AUTOSAR XML (schema 4-2-2)
package /STELLANTIS/EPT/ASWCs
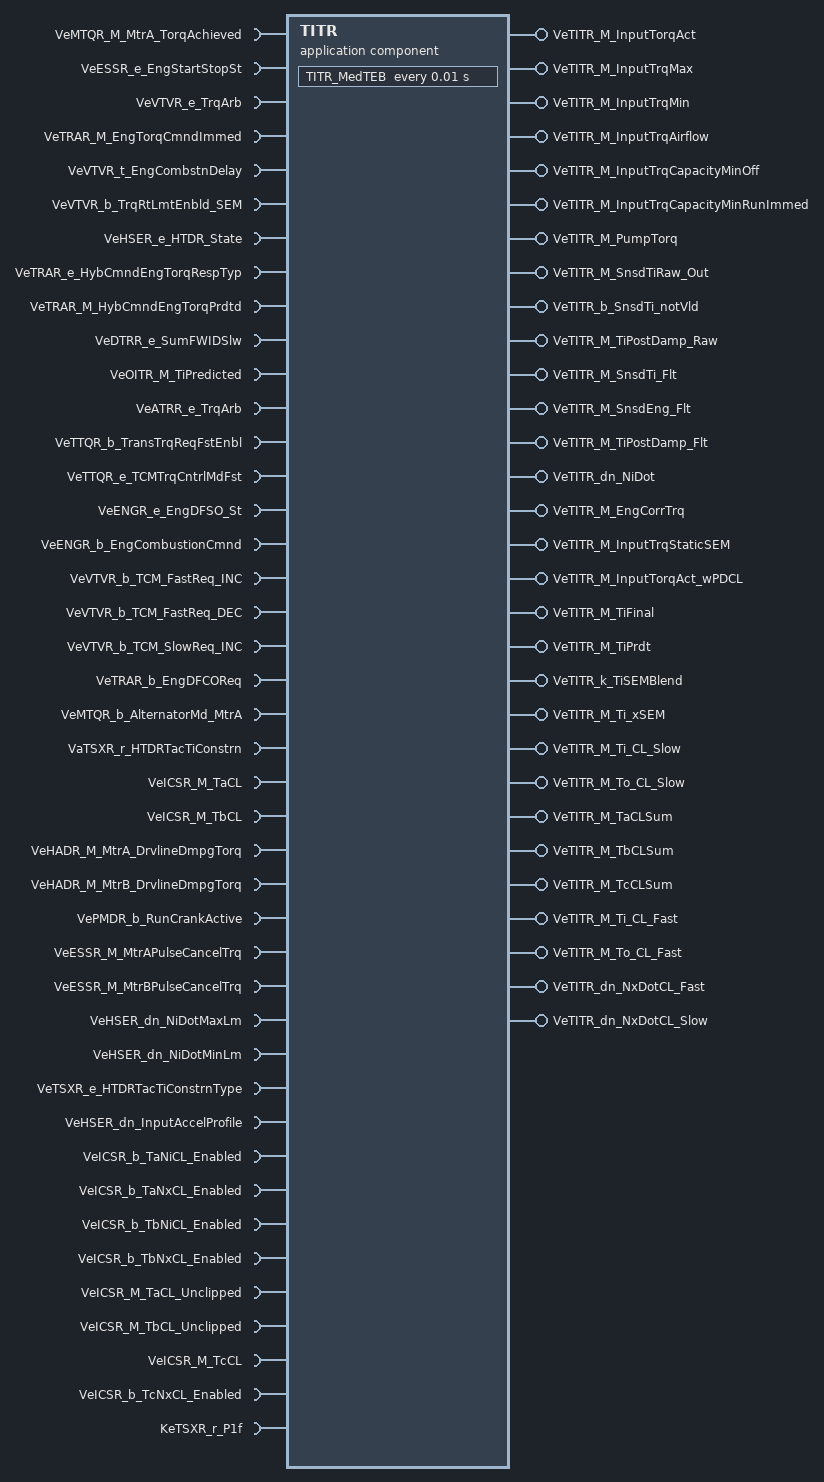
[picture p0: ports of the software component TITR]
  application sw component type TITR
    41 x require port:
      VeMTQR_M_MtrA_TorqAchieved: nonqueued-receiver-com-spec{data-element=Value, init-value=0}, required-interface=VeMTQR_M_MtrA_TorqAchieved
      VeESSR_e_EngStartStopSt: nonqueued-receiver-com-spec{data-element=Value, init-value=CeESSR_e_EngOff}, required-interface=VeESSR_e_EngStartStopSt
      VeVTVR_e_TrqArb: nonqueued-receiver-com-spec{data-element=Value, init-value=CeWTAR_e_ECM_TorqReqst}, required-interface=VeVTVR_e_TrqArb
      VeTRAR_M_EngTorqCmndImmed: nonqueued-receiver-com-spec{data-element=Value, init-value=0}, required-interface=VeTRAR_M_EngTorqCmndImmed
      VeVTVR_t_EngCombstnDelay: nonqueued-receiver-com-spec{data-element=Value, init-value=0}, required-interface=VeVTVR_t_EngCombstnDelay
      VeVTVR_b_TrqRtLmtEnbld_SEM: nonqueued-receiver-com-spec{data-element=Value, init-value=0}, required-interface=VeVTVR_b_TrqRtLmtEnbld_SEM
      VeHSER_e_HTDR_State: nonqueued-receiver-com-spec{data-element=Value, init-value=CeHSER_e_Neut_State}, required-interface=VeHSER_e_HTDR_State
      VeTRAR_e_HybCmndEngTorqRespTyp: nonqueued-receiver-com-spec{data-element=Value, init-value=CeTRAR_e_Inactive}, required-interface=VeTRAR_e_HybCmndEngTorqRespTyp
      VeTRAR_M_HybCmndEngTorqPrdtd: nonqueued-receiver-com-spec{data-element=Value, init-value=0}, required-interface=VeTRAR_M_HybCmndEngTorqPrdtd
      VeDTRR_e_SumFWIDSlw: nonqueued-receiver-com-spec{data-element=Value, init-value=CeDTRR_e_Potential}, required-interface=VeDTRR_e_SumFWIDSlw
      VeOITR_M_TiPredicted: nonqueued-receiver-com-spec{data-element=Value, init-value=0}, required-interface=VeOITR_M_TiPredicted
      VeATRR_e_TrqArb: nonqueued-receiver-com-spec{data-element=Value, init-value=CeWTAR_e_ECM_TorqReqst}, required-interface=VeATRR_e_TrqArb
      VeTTQR_b_TransTrqReqFstEnbl: nonqueued-receiver-com-spec{data-element=Value, init-value=0}, required-interface=VeTTQR_b_TransTrqReqFstEnbl
      VeTTQR_e_TCMTrqCntrlMdFst: nonqueued-receiver-com-spec{data-element=Value, init-value=CeTINR_e_None}, required-interface=VeTTQR_e_TCMTrqCntrlMdFst
      VeENGR_e_EngDFSO_St: nonqueued-receiver-com-spec{data-element=Value, init-value=CeENGR_e_DFSO_Disabled}, required-interface=VeENGR_e_EngDFSO_St
      VeENGR_b_EngCombustionCmnd: nonqueued-receiver-com-spec{data-element=Value, init-value=0}, required-interface=VeENGR_b_EngCombustionCmnd
      VeVTVR_b_TCM_FastReq_INC: nonqueued-receiver-com-spec{data-element=Value, init-value=0}, required-interface=VeVTVR_b_TCM_FastReq_INC
      VeVTVR_b_TCM_FastReq_DEC: nonqueued-receiver-com-spec{data-element=Value, init-value=0}, required-interface=VeVTVR_b_TCM_FastReq_DEC
      VeVTVR_b_TCM_SlowReq_INC: nonqueued-receiver-com-spec{data-element=Value, init-value=0}, required-interface=VeVTVR_b_TCM_SlowReq_INC
      VeTRAR_b_EngDFCOReq: nonqueued-receiver-com-spec{data-element=Value, init-value=0}, required-interface=VeTRAR_b_EngDFCOReq
      VeMTQR_b_AlternatorMd_MtrA: nonqueued-receiver-com-spec{data-element=Value, init-value=0}, required-interface=VeMTQR_b_AlternatorMd_MtrA
      VaTSXR_r_HTDRTacTiConstrn: nonqueued-receiver-com-spec{data-element=Value, init-value=114 x 0}, required-interface=VaTSXR_r_HTDRTacTiConstrn
      VeICSR_M_TaCL: nonqueued-receiver-com-spec{data-element=Value, init-value=0}, required-interface=VeICSR_M_TaCL
      VeICSR_M_TbCL: nonqueued-receiver-com-spec{data-element=Value, init-value=0}, required-interface=VeICSR_M_TbCL
      VeHADR_M_MtrA_DrvlineDmpgTorq: nonqueued-receiver-com-spec{data-element=Value, init-value=0}, required-interface=VeHADR_M_MtrA_DrvlineDmpgTorq
      VeHADR_M_MtrB_DrvlineDmpgTorq: nonqueued-receiver-com-spec{data-element=Value, init-value=0}, required-interface=VeHADR_M_MtrB_DrvlineDmpgTorq
      VePMDR_b_RunCrankActive: nonqueued-receiver-com-spec{data-element=Value, init-value=0}, required-interface=VePMDR_b_RunCrankActive
      VeESSR_M_MtrAPulseCancelTrq: nonqueued-receiver-com-spec{data-element=Value, init-value=0}, required-interface=VeESSR_M_MtrAPulseCancelTrq
      VeESSR_M_MtrBPulseCancelTrq: nonqueued-receiver-com-spec{data-element=Value, init-value=0}, required-interface=VeESSR_M_MtrBPulseCancelTrq
      VeHSER_dn_NiDotMaxLm: nonqueued-receiver-com-spec{data-element=Value, init-value=0}, required-interface=VeHSER_dn_NiDotMaxLm
      VeHSER_dn_NiDotMinLm: nonqueued-receiver-com-spec{data-element=Value, init-value=0}, required-interface=VeHSER_dn_NiDotMinLm
      VeTSXR_e_HTDRTacTiConstrnType: nonqueued-receiver-com-spec{data-element=Value, init-value=CeTSXR_e_Mode}, required-interface=VeTSXR_e_HTDRTacTiConstrnType
      VeHSER_dn_InputAccelProfile: nonqueued-receiver-com-spec{data-element=Value, init-value=0}, required-interface=VeHSER_dn_InputAccelProfile
      VeICSR_b_TaNiCL_Enabled: nonqueued-receiver-com-spec{data-element=Value, init-value=0}, required-interface=VeICSR_b_TaNiCL_Enabled
      VeICSR_b_TaNxCL_Enabled: nonqueued-receiver-com-spec{data-element=Value, init-value=0}, required-interface=VeICSR_b_TaNxCL_Enabled
      VeICSR_b_TbNiCL_Enabled: nonqueued-receiver-com-spec{data-element=Value, init-value=0}, required-interface=VeICSR_b_TbNiCL_Enabled
      VeICSR_b_TbNxCL_Enabled: nonqueued-receiver-com-spec{data-element=Value, init-value=0}, required-interface=VeICSR_b_TbNxCL_Enabled
      VeICSR_M_TaCL_Unclipped: nonqueued-receiver-com-spec{data-element=Value, init-value=0}, required-interface=VeICSR_M_TaCL_Unclipped
      VeICSR_M_TbCL_Unclipped: nonqueued-receiver-com-spec{data-element=Value, init-value=0}, required-interface=VeICSR_M_TbCL_Unclipped
      VeICSR_M_TcCL: nonqueued-receiver-com-spec{data-element=Value, init-value=0}, required-interface=VeICSR_M_TcCL
      VeICSR_b_TcNxCL_Enabled: nonqueued-receiver-com-spec{data-element=Value, init-value=0}, required-interface=VeICSR_b_TcNxCL_Enabled
    30 x provide port, all with nonqueued-sender-com-spec{data-element=Value, init-value=0}:
      VeTITR_M_InputTorqAct: variation-point={short-label=vpVeTITR_M_InputTorqAct, sw-syscond=1}, provided-interface=VeTITR_M_InputTorqAct
      VeTITR_M_InputTrqMax: variation-point={short-label=vpVeTITR_M_InputTrqMax, sw-syscond=1}, provided-interface=VeTITR_M_InputTrqMax
      VeTITR_M_InputTrqMin: variation-point={short-label=vpVeTITR_M_InputTrqMin, sw-syscond=1}, provided-interface=VeTITR_M_InputTrqMin
      VeTITR_M_InputTrqAirflow: variation-point={short-label=vpVeTITR_M_InputTrqAirflow, sw-syscond=1}, provided-interface=VeTITR_M_InputTrqAirflow
      VeTITR_M_InputTrqCapacityMinOff: variation-point={short-label=vpVeTITR_M_InputTrqCapacityMinOff, sw-syscond=1}, provided-interface=VeTITR_M_InputTrqCapacityMinOff
      VeTITR_M_InputTrqCapacityMinRunImmed: variation-point={short-label=vpVeTITR_M_InputTrqCapacityMinRunImmed, sw-syscond=1}, provided-interface=VeTITR_M_InputTrqCapacityMinRunImmed
      VeTITR_M_PumpTorq: variation-point={short-label=vpVeTITR_M_PumpTorq, sw-syscond=1}, provided-interface=VeTITR_M_PumpTorq
      VeTITR_M_SnsdTiRaw_Out: variation-point={short-label=vpVeTITR_M_SnsdTiRaw_Out, sw-syscond=1}, provided-interface=VeTITR_M_SnsdTiRaw_Out
      VeTITR_b_SnsdTi_notVld: variation-point={short-label=vpVeTITR_b_SnsdTi_notVld, sw-syscond=1}, provided-interface=VeTITR_b_SnsdTi_notVld
      VeTITR_M_TiPostDamp_Raw: variation-point={short-label=vpVeTITR_M_TiPostDamp_Raw, sw-syscond=1}, provided-interface=VeTITR_M_TiPostDamp_Raw
      VeTITR_M_SnsdTi_Flt: variation-point={short-label=vpVeTITR_M_SnsdTi_Flt, sw-syscond=1}, provided-interface=VeTITR_M_SnsdTi_Flt
      VeTITR_M_SnsdEng_Flt: variation-point={short-label=vpVeTITR_M_SnsdEng_Flt, sw-syscond=1}, provided-interface=VeTITR_M_SnsdEng_Flt
      VeTITR_M_TiPostDamp_Flt: variation-point={short-label=vpVeTITR_M_TiPostDamp_Flt, sw-syscond=1}, provided-interface=VeTITR_M_TiPostDamp_Flt
      VeTITR_dn_NiDot: variation-point={short-label=vpVeTITR_dn_NiDot, sw-syscond=1}, provided-interface=VeTITR_dn_NiDot
      VeTITR_M_EngCorrTrq: variation-point={short-label=vpVeTITR_M_EngCorrTrq, sw-syscond=1}, provided-interface=VeTITR_M_EngCorrTrq
      VeTITR_M_InputTrqStaticSEM: variation-point={short-label=vpVeTITR_M_InputTrqStaticSEM, sw-syscond=1}, provided-interface=VeTITR_M_InputTrqStaticSEM
      VeTITR_M_InputTorqAct_wPDCL: variation-point={short-label=vpVeTITR_M_InputTorqAct_wPDCL, sw-syscond=1}, provided-interface=VeTITR_M_InputTorqAct_wPDCL
      VeTITR_M_TiFinal: provided-interface=VeTITR_M_TiFinal
      VeTITR_M_TiPrdt: provided-interface=VeTITR_M_TiPrdt
      VeTITR_k_TiSEMBlend: provided-interface=VeTITR_k_TiSEMBlend
      VeTITR_M_Ti_xSEM: provided-interface=VeTITR_M_Ti_xSEM
      VeTITR_M_Ti_CL_Slow: provided-interface=VeTITR_M_Ti_CL_Slow
      VeTITR_M_To_CL_Slow: provided-interface=VeTITR_M_To_CL_Slow
      VeTITR_M_TaCLSum: provided-interface=VeTITR_M_TaCLSum
      VeTITR_M_TbCLSum: provided-interface=VeTITR_M_TbCLSum
      VeTITR_M_TcCLSum: provided-interface=VeTITR_M_TcCLSum
      VeTITR_M_Ti_CL_Fast: provided-interface=VeTITR_M_Ti_CL_Fast
      VeTITR_M_To_CL_Fast: provided-interface=VeTITR_M_To_CL_Fast
      VeTITR_dn_NxDotCL_Fast: provided-interface=VeTITR_dn_NxDotCL_Fast
      VeTITR_dn_NxDotCL_Slow: provided-interface=VeTITR_dn_NxDotCL_Slow
    require port KeTSXR_r_P1f: parameter-require-com-spec{init-value=KeTSXR_r_P1f_KeTSXR_r_P1f:2.55550003051758, parameter=KeTSXR_r_P1f}, required-interface=KeTSXR_r_P1f
    behavior IB_TITR: data-type-mapping=msADTtoIDTMapping, handle-termination-and-restart=NO-SUPPORT
      timing event Event_MedTEB: start-on-event=TITR_MedTEB, period=0.01
      init event Event_TITR_ac_Init: start-on-event=TITR_ac_Init
      init event Event_PUP: start-on-event=TITR_PUP
      init event Event_PwrOn: start-on-event=TITR_PwrOn
      4 x runnable:
        TITR_ac_Init
        TITR_PUP
          data-send-points:
            13 x access:
              OUT_VeTITR_M_InputTorqAct_Value: accessed-variable=VeTITR_M_InputTorqAct.Value, variation-point={short-label=vpOUT_VeTITR_M_InputTorqAct_Value, sw-syscond=1}
              OUT_VeTITR_M_InputTrqMax_Value: accessed-variable=VeTITR_M_InputTrqMax.Value, variation-point={short-label=vpOUT_VeTITR_M_InputTrqMax_Value, sw-syscond=1}
              OUT_VeTITR_M_InputTrqMin_Value: accessed-variable=VeTITR_M_InputTrqMin.Value, variation-point={short-label=vpOUT_VeTITR_M_InputTrqMin_Value, sw-syscond=1}
              OUT_VeTITR_M_PumpTorq_Value: accessed-variable=VeTITR_M_PumpTorq.Value, variation-point={short-label=vpOUT_VeTITR_M_PumpTorq_Value, sw-syscond=1}
              OUT_VeTITR_M_InputTrqAirflow_Value: accessed-variable=VeTITR_M_InputTrqAirflow.Value, variation-point={short-label=vpOUT_VeTITR_M_InputTrqAirflow_Value, sw-syscond=1}
              OUT_VeTITR_M_InputTrqCapacityMinOff_Value: accessed-variable=VeTITR_M_InputTrqCapacityMinOff.Value, variation-point={short-label=vpOUT_VeTITR_M_InputTrqCapacityMinOff_Value, sw-syscond=1}
              OUT_VeTITR_M_InputTrqCapacityMinRunImmed_Value: accessed-variable=VeTITR_M_InputTrqCapacityMinRunImmed.Value, variation-point={short-label=vpOUT_VeTITR_M_InputTrqCapacityMinRunImmed_Value, sw-syscond=1}
              OUT_VeTITR_M_EngCorrTrq_Value: accessed-variable=VeTITR_M_EngCorrTrq.Value, variation-point={short-label=vpOUT_VeTITR_M_EngCorrTrq_Value, sw-syscond=1}
              OUT_VeTITR_M_InputTrqStaticSEM_Value: accessed-variable=VeTITR_M_InputTrqStaticSEM.Value, variation-point={short-label=vpOUT_VeTITR_M_InputTrqStaticSEM_Value, sw-syscond=1}
              OUT_VeTITR_M_InputTorqAct_wPDCL_Value: accessed-variable=VeTITR_M_InputTorqAct_wPDCL.Value, variation-point={short-label=vpOUT_VeTITR_M_InputTorqAct_wPDCL_Value, sw-syscond=1}
              OUT_VeTITR_M_SnsdTiRaw_Out_Value: accessed-variable=VeTITR_M_SnsdTiRaw_Out.Value, variation-point={short-label=vpOUT_VeTITR_M_SnsdTiRaw_Out_Value, sw-syscond=1}
              OUT_VeTITR_M_TiPostDamp_Raw_Value: accessed-variable=VeTITR_M_TiPostDamp_Raw.Value, variation-point={short-label=vpOUT_VeTITR_M_TiPostDamp_Raw_Value, sw-syscond=1}
              OUT_VeTITR_b_SnsdTi_notVld_Value: accessed-variable=VeTITR_b_SnsdTi_notVld.Value, variation-point={short-label=vpOUT_VeTITR_b_SnsdTi_notVld_Value, sw-syscond=1}
        TITR_PwrOn
          data-send-points:
            30 x access:
              OUT_VeTITR_M_InputTorqAct_Value: accessed-variable=VeTITR_M_InputTorqAct.Value, variation-point={short-label=vpOUT_VeTITR_M_InputTorqAct_Value, sw-syscond=1}
              OUT_VeTITR_M_InputTrqMax_Value: accessed-variable=VeTITR_M_InputTrqMax.Value, variation-point={short-label=vpOUT_VeTITR_M_InputTrqMax_Value, sw-syscond=1}
              OUT_VeTITR_M_InputTrqMin_Value: accessed-variable=VeTITR_M_InputTrqMin.Value, variation-point={short-label=vpOUT_VeTITR_M_InputTrqMin_Value, sw-syscond=1}
              OUT_VeTITR_M_PumpTorq_Value: accessed-variable=VeTITR_M_PumpTorq.Value, variation-point={short-label=vpOUT_VeTITR_M_PumpTorq_Value, sw-syscond=1}
              OUT_VeTITR_M_InputTrqAirflow_Value: accessed-variable=VeTITR_M_InputTrqAirflow.Value, variation-point={short-label=vpOUT_VeTITR_M_InputTrqAirflow_Value, sw-syscond=1}
              OUT_VeTITR_M_InputTrqCapacityMinOff_Value: accessed-variable=VeTITR_M_InputTrqCapacityMinOff.Value, variation-point={short-label=vpOUT_VeTITR_M_InputTrqCapacityMinOff_Value, sw-syscond=1}
              OUT_VeTITR_M_InputTrqCapacityMinRunImmed_Value: accessed-variable=VeTITR_M_InputTrqCapacityMinRunImmed.Value, variation-point={short-label=vpOUT_VeTITR_M_InputTrqCapacityMinRunImmed_Value, sw-syscond=1}
              OUT_VeTITR_M_EngCorrTrq_Value: accessed-variable=VeTITR_M_EngCorrTrq.Value, variation-point={short-label=vpOUT_VeTITR_M_EngCorrTrq_Value, sw-syscond=1}
              OUT_VeTITR_M_InputTrqStaticSEM_Value: accessed-variable=VeTITR_M_InputTrqStaticSEM.Value, variation-point={short-label=vpOUT_VeTITR_M_InputTrqStaticSEM_Value, sw-syscond=1}
              OUT_VeTITR_M_InputTorqAct_wPDCL_Value: accessed-variable=VeTITR_M_InputTorqAct_wPDCL.Value, variation-point={short-label=vpOUT_VeTITR_M_InputTorqAct_wPDCL_Value, sw-syscond=1}
              OUT_VeTITR_M_SnsdTiRaw_Out_Value: accessed-variable=VeTITR_M_SnsdTiRaw_Out.Value, variation-point={short-label=vpOUT_VeTITR_M_SnsdTiRaw_Out_Value, sw-syscond=1}
              OUT_VeTITR_M_TiPostDamp_Raw_Value: accessed-variable=VeTITR_M_TiPostDamp_Raw.Value, variation-point={short-label=vpOUT_VeTITR_M_TiPostDamp_Raw_Value, sw-syscond=1}
              OUT_VeTITR_b_SnsdTi_notVld_Value: accessed-variable=VeTITR_b_SnsdTi_notVld.Value, variation-point={short-label=vpOUT_VeTITR_b_SnsdTi_notVld_Value, sw-syscond=1}
              OUT_VeTITR_dn_NiDot_Value: accessed-variable=VeTITR_dn_NiDot.Value, variation-point={short-label=vpOUT_VeTITR_dn_NiDot_Value, sw-syscond=1}
              OUT_VeTITR_M_TiPostDamp_Flt_Value: accessed-variable=VeTITR_M_TiPostDamp_Flt.Value, variation-point={short-label=vpOUT_VeTITR_M_TiPostDamp_Flt_Value, sw-syscond=1}
              OUT_VeTITR_M_SnsdTi_Flt_Value: accessed-variable=VeTITR_M_SnsdTi_Flt.Value, variation-point={short-label=vpOUT_VeTITR_M_SnsdTi_Flt_Value, sw-syscond=1}
              OUT_VeTITR_M_SnsdEng_Flt_Value: accessed-variable=VeTITR_M_SnsdEng_Flt.Value, variation-point={short-label=vpOUT_VeTITR_M_SnsdEng_Flt_Value, sw-syscond=1}
              OUT_VeTITR_M_TiFinal_Value: accessed-variable=VeTITR_M_TiFinal.Value
              OUT_VeTITR_M_TiPrdt_Value: accessed-variable=VeTITR_M_TiPrdt.Value
              OUT_VeTITR_k_TiSEMBlend_Value: accessed-variable=VeTITR_k_TiSEMBlend.Value
              OUT_VeTITR_M_Ti_xSEM_Value: accessed-variable=VeTITR_M_Ti_xSEM.Value
              OUT_VeTITR_M_Ti_CL_Slow_Value: accessed-variable=VeTITR_M_Ti_CL_Slow.Value
              OUT_VeTITR_M_To_CL_Slow_Value: accessed-variable=VeTITR_M_To_CL_Slow.Value
              OUT_VeTITR_M_TaCLSum_Value: accessed-variable=VeTITR_M_TaCLSum.Value
              OUT_VeTITR_M_TbCLSum_Value: accessed-variable=VeTITR_M_TbCLSum.Value
              OUT_VeTITR_M_TcCLSum_Value: accessed-variable=VeTITR_M_TcCLSum.Value
              OUT_VeTITR_M_Ti_CL_Fast_Value: accessed-variable=VeTITR_M_Ti_CL_Fast.Value
              OUT_VeTITR_M_To_CL_Fast_Value: accessed-variable=VeTITR_M_To_CL_Fast.Value
              OUT_VeTITR_dn_NxDotCL_Fast_Value: accessed-variable=VeTITR_dn_NxDotCL_Fast.Value
              OUT_VeTITR_dn_NxDotCL_Slow_Value: accessed-variable=VeTITR_dn_NxDotCL_Slow.Value
        TITR_MedTEB
          data-receive-point-by-arguments:
            40 x access:
              IN_VaTSXR_r_HTDRTacTiConstrn_Value: accessed-variable=VaTSXR_r_HTDRTacTiConstrn.Value
              IN_VeATRR_e_TrqArb_Value: accessed-variable=VeATRR_e_TrqArb.Value
              IN_VeDTRR_e_SumFWIDSlw_Value: accessed-variable=VeDTRR_e_SumFWIDSlw.Value
              IN_VeENGR_b_EngCombustionCmnd_Value: accessed-variable=VeENGR_b_EngCombustionCmnd.Value
              IN_VeENGR_e_EngDFSO_St_Value: accessed-variable=VeENGR_e_EngDFSO_St.Value
              IN_VeESSR_M_MtrAPulseCancelTrq_Value: accessed-variable=VeESSR_M_MtrAPulseCancelTrq.Value
              IN_VeESSR_M_MtrBPulseCancelTrq_Value: accessed-variable=VeESSR_M_MtrBPulseCancelTrq.Value
              IN_VeESSR_e_EngStartStopSt_Value: accessed-variable=VeESSR_e_EngStartStopSt.Value
              IN_VeHADR_M_MtrA_DrvlineDmpgTorq_Value: accessed-variable=VeHADR_M_MtrA_DrvlineDmpgTorq.Value
              IN_VeHADR_M_MtrB_DrvlineDmpgTorq_Value: accessed-variable=VeHADR_M_MtrB_DrvlineDmpgTorq.Value
              IN_VeHSER_dn_InputAccelProfile_Value: accessed-variable=VeHSER_dn_InputAccelProfile.Value
              IN_VeHSER_dn_NiDotMaxLm_Value: accessed-variable=VeHSER_dn_NiDotMaxLm.Value
              IN_VeHSER_dn_NiDotMinLm_Value: accessed-variable=VeHSER_dn_NiDotMinLm.Value
              IN_VeHSER_e_HTDR_State_Value: accessed-variable=VeHSER_e_HTDR_State.Value
              IN_VeICSR_M_TaCL_Value: accessed-variable=VeICSR_M_TaCL.Value
              IN_VeICSR_M_TaCL_Unclipped_Value: accessed-variable=VeICSR_M_TaCL_Unclipped.Value
              IN_VeICSR_M_TbCL_Value: accessed-variable=VeICSR_M_TbCL.Value
              IN_VeICSR_M_TbCL_Unclipped_Value: accessed-variable=VeICSR_M_TbCL_Unclipped.Value
              IN_VeICSR_M_TcCL_Value: accessed-variable=VeICSR_M_TcCL.Value
              IN_VeICSR_b_TaNiCL_Enabled_Value: accessed-variable=VeICSR_b_TaNiCL_Enabled.Value
              IN_VeICSR_b_TaNxCL_Enabled_Value: accessed-variable=VeICSR_b_TaNxCL_Enabled.Value
              IN_VeICSR_b_TbNiCL_Enabled_Value: accessed-variable=VeICSR_b_TbNiCL_Enabled.Value
              IN_VeICSR_b_TbNxCL_Enabled_Value: accessed-variable=VeICSR_b_TbNxCL_Enabled.Value
              IN_VeICSR_b_TcNxCL_Enabled_Value: accessed-variable=VeICSR_b_TcNxCL_Enabled.Value
              IN_VeMTQR_M_MtrA_TorqAchieved_Value: accessed-variable=VeMTQR_M_MtrA_TorqAchieved.Value
              IN_VeMTQR_b_AlternatorMd_MtrA_Value: accessed-variable=VeMTQR_b_AlternatorMd_MtrA.Value
              IN_VeOITR_M_TiPredicted_Value: accessed-variable=VeOITR_M_TiPredicted.Value
              IN_VePMDR_b_RunCrankActive_Value: accessed-variable=VePMDR_b_RunCrankActive.Value
              IN_VeTRAR_M_EngTorqCmndImmed_Value: accessed-variable=VeTRAR_M_EngTorqCmndImmed.Value
              IN_VeTRAR_M_HybCmndEngTorqPrdtd_Value: accessed-variable=VeTRAR_M_HybCmndEngTorqPrdtd.Value
              IN_VeTRAR_b_EngDFCOReq_Value: accessed-variable=VeTRAR_b_EngDFCOReq.Value
              IN_VeTRAR_e_HybCmndEngTorqRespTyp_Value: accessed-variable=VeTRAR_e_HybCmndEngTorqRespTyp.Value
              IN_VeTSXR_e_HTDRTacTiConstrnType_Value: accessed-variable=VeTSXR_e_HTDRTacTiConstrnType.Value
              IN_VeTTQR_e_TCMTrqCntrlMdFst_Value: accessed-variable=VeTTQR_e_TCMTrqCntrlMdFst.Value
              IN_VeVTVR_b_TCM_FastReq_DEC_Value: accessed-variable=VeVTVR_b_TCM_FastReq_DEC.Value
              IN_VeVTVR_b_TCM_FastReq_INC_Value: accessed-variable=VeVTVR_b_TCM_FastReq_INC.Value
              IN_VeVTVR_b_TCM_SlowReq_INC_Value: accessed-variable=VeVTVR_b_TCM_SlowReq_INC.Value
              IN_VeVTVR_b_TrqRtLmtEnbld_SEM_Value: accessed-variable=VeVTVR_b_TrqRtLmtEnbld_SEM.Value
              IN_VeVTVR_e_TrqArb_Value: accessed-variable=VeVTVR_e_TrqArb.Value
              IN_VeVTVR_t_EngCombstnDelay_Value: accessed-variable=VeVTVR_t_EngCombstnDelay.Value
          data-send-points:
            30 x access:
              OUT_VeTITR_M_InputTorqAct_Value: accessed-variable=VeTITR_M_InputTorqAct.Value, variation-point={short-label=vpOUT_VeTITR_M_InputTorqAct_Value, sw-syscond=1}
              OUT_VeTITR_M_InputTrqMax_Value: accessed-variable=VeTITR_M_InputTrqMax.Value, variation-point={short-label=vpOUT_VeTITR_M_InputTrqMax_Value, sw-syscond=1}
              OUT_VeTITR_M_InputTrqMin_Value: accessed-variable=VeTITR_M_InputTrqMin.Value, variation-point={short-label=vpOUT_VeTITR_M_InputTrqMin_Value, sw-syscond=1}
              OUT_VeTITR_M_PumpTorq_Value: accessed-variable=VeTITR_M_PumpTorq.Value, variation-point={short-label=vpOUT_VeTITR_M_PumpTorq_Value, sw-syscond=1}
              OUT_VeTITR_M_InputTrqAirflow_Value: accessed-variable=VeTITR_M_InputTrqAirflow.Value, variation-point={short-label=vpOUT_VeTITR_M_InputTrqAirflow_Value, sw-syscond=1}
              OUT_VeTITR_M_InputTrqCapacityMinOff_Value: accessed-variable=VeTITR_M_InputTrqCapacityMinOff.Value, variation-point={short-label=vpOUT_VeTITR_M_InputTrqCapacityMinOff_Value, sw-syscond=1}
              OUT_VeTITR_M_InputTrqCapacityMinRunImmed_Value: accessed-variable=VeTITR_M_InputTrqCapacityMinRunImmed.Value, variation-point={short-label=vpOUT_VeTITR_M_InputTrqCapacityMinRunImmed_Value, sw-syscond=1}
              OUT_VeTITR_M_EngCorrTrq_Value: accessed-variable=VeTITR_M_EngCorrTrq.Value, variation-point={short-label=vpOUT_VeTITR_M_EngCorrTrq_Value, sw-syscond=1}
              OUT_VeTITR_M_InputTrqStaticSEM_Value: accessed-variable=VeTITR_M_InputTrqStaticSEM.Value, variation-point={short-label=vpOUT_VeTITR_M_InputTrqStaticSEM_Value, sw-syscond=1}
              OUT_VeTITR_M_InputTorqAct_wPDCL_Value: accessed-variable=VeTITR_M_InputTorqAct_wPDCL.Value, variation-point={short-label=vpOUT_VeTITR_M_InputTorqAct_wPDCL_Value, sw-syscond=1}
              OUT_VeTITR_M_TiFinal_Value: accessed-variable=VeTITR_M_TiFinal.Value
              OUT_VeTITR_M_TiPrdt_Value: accessed-variable=VeTITR_M_TiPrdt.Value
              OUT_VeTITR_k_TiSEMBlend_Value: accessed-variable=VeTITR_k_TiSEMBlend.Value
              OUT_VeTITR_M_Ti_xSEM_Value: accessed-variable=VeTITR_M_Ti_xSEM.Value
              OUT_VeTITR_M_Ti_CL_Slow_Value: accessed-variable=VeTITR_M_Ti_CL_Slow.Value
              OUT_VeTITR_M_To_CL_Slow_Value: accessed-variable=VeTITR_M_To_CL_Slow.Value
              OUT_VeTITR_M_TaCLSum_Value: accessed-variable=VeTITR_M_TaCLSum.Value
              OUT_VeTITR_M_TbCLSum_Value: accessed-variable=VeTITR_M_TbCLSum.Value
              OUT_VeTITR_M_TcCLSum_Value: accessed-variable=VeTITR_M_TcCLSum.Value
              OUT_VeTITR_M_Ti_CL_Fast_Value: accessed-variable=VeTITR_M_Ti_CL_Fast.Value
              OUT_VeTITR_M_To_CL_Fast_Value: accessed-variable=VeTITR_M_To_CL_Fast.Value
              OUT_VeTITR_dn_NxDotCL_Fast_Value: accessed-variable=VeTITR_dn_NxDotCL_Fast.Value
              OUT_VeTITR_dn_NxDotCL_Slow_Value: accessed-variable=VeTITR_dn_NxDotCL_Slow.Value
              OUT_VeTITR_M_SnsdTiRaw_Out_Value: accessed-variable=VeTITR_M_SnsdTiRaw_Out.Value, variation-point={short-label=vpOUT_VeTITR_M_SnsdTiRaw_Out_Value, sw-syscond=1}
              OUT_VeTITR_M_TiPostDamp_Raw_Value: accessed-variable=VeTITR_M_TiPostDamp_Raw.Value, variation-point={short-label=vpOUT_VeTITR_M_TiPostDamp_Raw_Value, sw-syscond=1}
              OUT_VeTITR_b_SnsdTi_notVld_Value: accessed-variable=VeTITR_b_SnsdTi_notVld.Value, variation-point={short-label=vpOUT_VeTITR_b_SnsdTi_notVld_Value, sw-syscond=1}
              OUT_VeTITR_dn_NiDot_Value: accessed-variable=VeTITR_dn_NiDot.Value, variation-point={short-label=vpOUT_VeTITR_dn_NiDot_Value, sw-syscond=1}
              OUT_VeTITR_M_TiPostDamp_Flt_Value: accessed-variable=VeTITR_M_TiPostDamp_Flt.Value, variation-point={short-label=vpOUT_VeTITR_M_TiPostDamp_Flt_Value, sw-syscond=1}
              OUT_VeTITR_M_SnsdTi_Flt_Value: accessed-variable=VeTITR_M_SnsdTi_Flt.Value, variation-point={short-label=vpOUT_VeTITR_M_SnsdTi_Flt_Value, sw-syscond=1}
              OUT_VeTITR_M_SnsdEng_Flt_Value: accessed-variable=VeTITR_M_SnsdEng_Flt.Value, variation-point={short-label=vpOUT_VeTITR_M_SnsdEng_Flt_Value, sw-syscond=1}
          parameter access CALPRM_KeTSXR_r_P1f_KeTSXR_r_P1f: accessed-parameter=KeTSXR_r_P1f.KeTSXR_r_P1f
      variation point proxy Variant_TITR_FUNC: category=CONDITION, condition-access=0
      variation point proxy Variant_TITR_NF: category=CONDITION, condition-access=1
      variation point proxy Variant_TITR_UsePumpTrqAsLoad: category=CONDITION, condition-access=0
